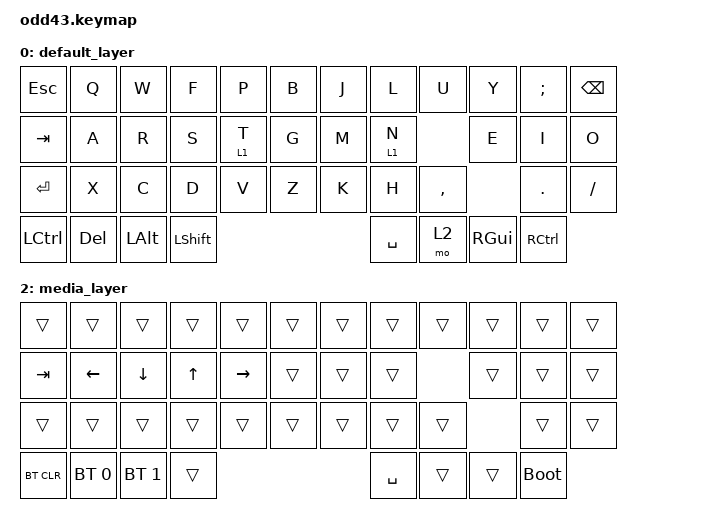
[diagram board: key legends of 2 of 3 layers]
/*
 * Copyright (c) 2020 The ZMK Contributors
 *
 * SPDX-License-Identifier: MIT
 */

#include <behaviors.dtsi>
#include <dt-bindings/zmk/keys.h>
#include <dt-bindings/zmk/bt.h>
#include <dt-bindings/zmk/rgb.h>

#define DEFAULT 0
#define LOWER 1
#define RAISE 2


/ {
    keymap{
    compatible = "zmk,keymap";

    default_layer {
            bindings = <
    &kp ESC &kp Q &kp W &kp F &kp P &kp B &kp J &kp L &kp U &kp Y &kp SEMI &kp BSPC
    &kp TAB &kp A &kp R &kp S &lt 1 T &kp G &kp M &lt 1 N &kp E &kp I &kp O
    &kp RET &kp X &kp C &kp D &kp V &kp Z &kp K &kp H &kp COMMA &kp DOT &kp FSLH
    &kp LCTL &kp DEL &kp LALT &kp LSHFT &kp SPACE &mo 2 &kp RGUI &kp RCTL
            >;
        };

    nav_layer {
            bindings = <
    &kp GRAVE &kp N1 &kp N2 &kp N3 &kp N4 &kp N5 &kp N6 &kp N7 &kp N8 &kp N9 &kp N0 &kp BSPC
    &trans &CAPSLOCK EXCL &kp AT &kp HASH &kp DLLR &kp PRCNT &kp CARET &kp AMPS &kp STAR &kp LPAR &kp RPAR
    &kp LSHFT &kp BSLH &kp SEMI &kp LBRC &kp LBKT &kp LPAR &kp RPAR &kp RBKT &kp RBRC &kp SQT &kp GRAVE &trans
    &kp LCTL &kp LGUI &kp LALT &kp LSHFT &kp SPACE &trans &trans &trans
            >;
        };

        media_layer {
            bindings = <
    &trans  &trans  &trans  &trans  &trans  &trans  &trans  &trans  &trans  &trans  &trans  &trans 
    &kp TAB &kp LEFT &kp DOWN &kp UP &kp RIGHT &trans  &trans  &trans  &trans  &trans  &trans
    &trans &trans  &trans &trans  &trans &trans &trans &trans &trans &trans &trans
    &bt BT_CLR &bt BT_SEL 0 &bt BT_SEL 1 &trans &kp SPACE &trans &trans &bootloader
            >;
        };
    };
};
